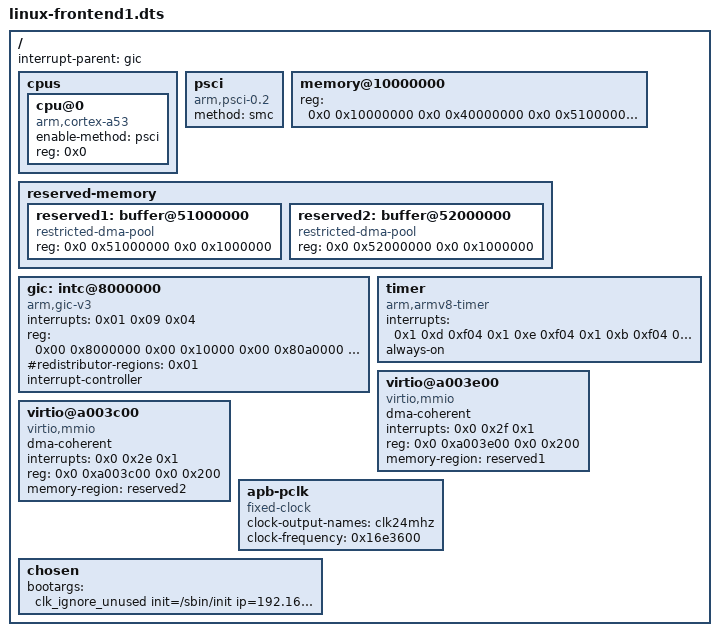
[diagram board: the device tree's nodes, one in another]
/dts-v1/;

/ {
	#size-cells = <0x2>;
	#address-cells = <0x2>;
	interrupt-parent = <&gic>;

	cpus {
		#size-cells = <0x0>;
		#address-cells = <0x1>;

		cpu@0 {
			compatible = "arm,cortex-a53", "arm,armv8";
			device_type = "cpu";
			enable-method = "psci";
			reg = <0x0>;
		};
	};

	psci {
		compatible = "arm,psci-0.2";
		method = "smc";
	};
	
	memory@10000000 {
		device_type = "memory";
		reg = <0x0 0x10000000 0x0 0x40000000
			   0x0 0x51000000 0x0 0x02000000>;
	};
	
	reserved-memory {
		#address-cells = <0x2>;
		#size-cells = <0x2>;
		ranges;
	
		reserved1: buffer@51000000 {
		    compatible = "restricted-dma-pool";			
		    reg = <0x0 0x51000000 0x0 0x1000000>;
		};

		reserved2: buffer@52000000 {
		    compatible = "restricted-dma-pool";			
		    reg = <0x0 0x52000000 0x0 0x1000000>;
		};
    };

    gic: intc@8000000 {
		interrupts = <0x01 0x09 0x04>;
		reg = <0x00 0x8000000 0x00 0x10000 0x00 0x80a0000 0x00 0xf60000>;
		#redistributor-regions = <0x01>;
		compatible = "arm,gic-v3";
		ranges;
		#size-cells = <0x02>;
		#address-cells = <0x02>;
		interrupt-controller;
		#interrupt-cells = <0x03>;
	};

	timer {
		interrupts = <0x1 0xd 0xf04 0x1 0xe 0xf04 0x1 0xb 0xf04 0x1 0xa 0xf04>;
		always-on;
		compatible = "arm,armv8-timer", "arm,armv7-timer";
	};

	virtio@a003e00 {
		dma-coherent;
		interrupts = <0x0 0x2f 0x1>;
		reg = <0x0 0xa003e00 0x0 0x200>;
		compatible = "virtio,mmio";
		memory-region = <&reserved1>;	
	};

	virtio@a003c00 {
		dma-coherent;
		interrupts = <0x0 0x2e 0x1>;
		reg = <0x0 0xa003c00 0x0 0x200>;
		compatible = "virtio,mmio";
		memory-region = <&reserved2>;	
	};
	
	apb-pclk {
		phandle = <0x8000>;
		clock-output-names = "clk24mhz";
		clock-frequency = <0x16e3600>;
		#clock-cells = <0x00>;
		compatible = "fixed-clock";
	};
	
	chosen {
        bootargs = "clk_ignore_unused init=/sbin/init ip=192.168.42.16";
	};

};
